# qmss register map
Vendor: Texas Instruments
Peripheral module from a debugger description file (folder Keystone).
Registers are 32-bit, read-write, no defined reset value unless marked. A register's access mark holds for its fields unless they carry their own. Offsets are as the file gives them; lines under a group give offsets from that group; [hi:lo] are bit positions; {n}, {i} and the like mark numbered series; 'fields as' and 'values as' point back to an identical list; <NAME> marks a mode.

## QMSS
0x00 QUEUE_STATUS_CONFIG_REG_A ro — (1 of 8192, stride 16)
  [18:0] queue_entry_count — This field indicates how many packets are currently queued on the queue.
0x04 QUEUE_STATUS_CONFIG_REG_B ro — (1 of 8192, stride 16)
  [31:0] queue_byte_count — This field indicates how many bytes total are contained in all of the packets which are currently queued on this queue.
0x08 QUEUE_STATUS_CONFIG_REG_C ro — (1 of 8192, stride 16)
  [16:0] packet_size — This field indicates the packet size of the head element of a queue.
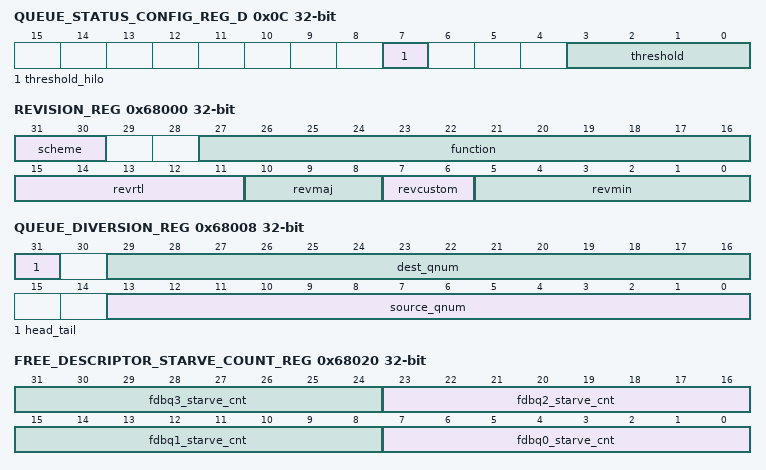
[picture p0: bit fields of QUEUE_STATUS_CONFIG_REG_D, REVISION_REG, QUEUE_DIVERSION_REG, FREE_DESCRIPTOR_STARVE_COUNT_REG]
0x0C QUEUE_STATUS_CONFIG_REG_D — (1 of 8192, stride 16)
  [7] threshold_hilo — This field indicates whether the number of items in a queue should be greater than equal to or less than the threshold before the queue_ecnt_status\[queue\] bit is asserted.
  [3:0] threshold — This field indicates the threshold at which the queue threshold pin is asserted.
0x68000 REVISION_REG ro
  [31:30] scheme — Scheme that this register is compliant with
  [27:16] function
  [15:11] revrtl — Major revision
  [10:8] revmaj — Major revision
  [7:6] revcustom — Custom revision
  [5:0] revmin — Minor revision
0x68008 QUEUE_DIVERSION_REG wo
  [31] head_tail — Indicates whether queue contents should be merged on to head or tail of destination queue. Clear this field for head and set for tail.
  [29:16] dest_qnum — Destination queue number
  [13:0] source_qnum — Source queue number
0x6800C LINKING_RAM_REGION_0_BASE_ADDRESS_REG
  [31:0] region0_base — This field stores the base address for the first region of the linking RAM. This may be anywhere in 32-bit address space but would be typically located in on-chip memory.
0x68010 LINKING_RAM_REGION_0_SIZE_REG
  [18:0] region0_size — This field indicates the number of entries that are contained in the linking RAM region 0
0x68014 LINKING_RAM_REGION_1_BASE_ADDRESS_REG
  [31:0] region1_base — This field stores the base address for the first region of the linking RAM. This may be anywhere in 32-bit address space but would be typically located in on-chip memory.
0x68020 FREE_DESCRIPTOR_STARVE_COUNT_REG ro — (1 of 16, stride 4)
  [8n+7:8n] fdbq{n}_starve_cnt (n=0..3) — This field increments each time the Free Descriptor/Buffer Queue \[N mod 4\]=={n} is read while it is empty. This field is cleared when read.
0x6A000 MEMORY_REGION_BASE_ADDRESS_REG — (1 of 20, stride 16)
  [31:0] regR_base — This field contains the base address of the memory region R.
0x6A004 MEMORY_REGION_START_INDEX_REG — (1 of 20, stride 16)
  [18:0] start_index — This field indicates where in linking RAM does the descriptor linking information corresponding to memory region R starts.
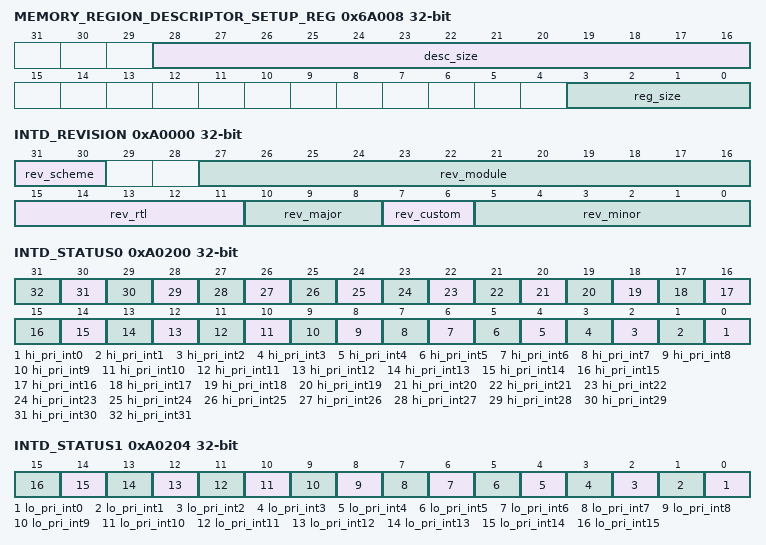
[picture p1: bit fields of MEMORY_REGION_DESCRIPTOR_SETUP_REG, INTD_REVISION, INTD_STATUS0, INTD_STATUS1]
0x6A008 MEMORY_REGION_DESCRIPTOR_SETUP_REG — (1 of 20, stride 16)
  [28:16] desc_size — This field indicates the size of each descriptor in this memory region. The value programmed is the multipler minus one that needs to be applied to 16 to get the actual descriptor size.
  [3:0] reg_size — This field indicates the size of the memory region (in terms of number of descriptors). It is an encoded value that specifies region size as 2^\[5+reg_size\] number of descriptors.
0xA0000 INTD_REVISION ro — (1 of 1, stride 0)
  [31:30] rev_scheme — Scheme
  [27:16] rev_module — Module ID
  [15:11] rev_rtl — RTL revisions
  [10:8] rev_major — Major revision
  [7:6] rev_custom — Custom revision
  [5:0] rev_minor — Minor revision
0xA0010 INTD_EOI — (1 of 1, stride 0)
  [7:0] eoi_vector — End of Interrupt Vector
0xA0200 INTD_STATUS0 — (1 of 1, stride 0)
  [n] hi_pri_int{n} (n=0..31) — Int {n} status
0xA0204 INTD_STATUS1 — (1 of 1, stride 0)
  [n] lo_pri_int{n} (n=0..15) — Int {n} status
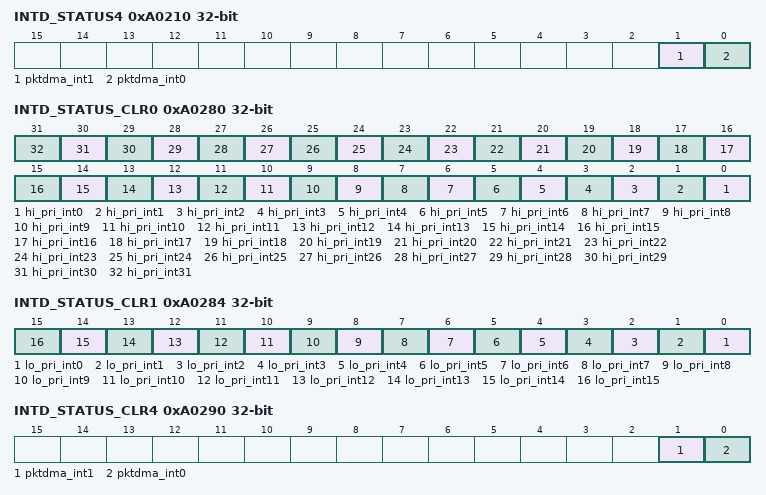
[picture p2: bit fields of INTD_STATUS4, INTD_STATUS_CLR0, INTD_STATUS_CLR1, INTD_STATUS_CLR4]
0xA0210 INTD_STATUS4 — (1 of 1, stride 0)
  [1] pktdma_int1 — Int 1 status
  [0] pktdma_int0 — Int 0 status
0xA0280 INTD_STATUS_CLR0 — (1 of 1, stride 0)
  [n] hi_pri_int{n} (n=0..31) — Int {n} status
0xA0284 INTD_STATUS_CLR1 — (1 of 1, stride 0)
  [n] lo_pri_int{n} (n=0..15) — Int {n} status
0xA0290 INTD_STATUS_CLR4 — (1 of 1, stride 0)
  [1] pktdma_int1 — Int 1 status
  [0] pktdma_int0 — Int 0 status
0xA0300 INTD_INTCNT ro — (1 of 1, stride 0)
  [1:0] intcnt_host_cnt_in_intr — Interrupt Count for host_cnt_in_intr (write to decrement)
